# timer register map
Vendor: Texas Instruments
Peripheral module from a debugger description file (folder Keystone2).
Registers are 32-bit, read-write, no defined reset value unless marked. A register's access mark holds for its fields unless they carry their own. Offsets are as the file gives them; lines under a group give offsets from that group; [hi:lo] are bit positions; {n}, {i} and the like mark numbered series; 'fields as' and 'values as' point back to an identical list; <NAME> marks a mode.

## TIMER_19
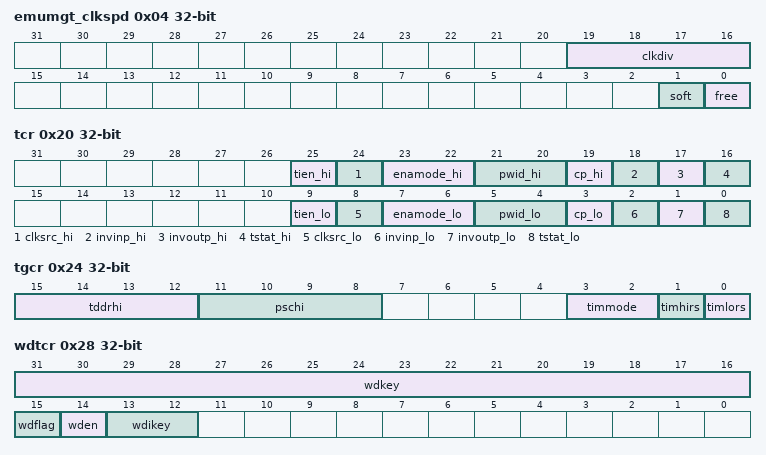
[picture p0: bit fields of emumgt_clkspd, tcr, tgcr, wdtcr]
0x04 emumgt_clkspd
  [19:16] clkdiv, [1] soft, [0] free
0x10 cntlo
  [31:0] cnt
0x14 cnthi
  [31:0] cnt
0x18 prdlo
0x1C prdhi
0x20 tcr
  [25] tien_hi, [24] clksrc_hi, [23:22] enamode_hi, [21:20] pwid_hi, [19] cp_hi, [18] invinp_hi, [17] invoutp_hi, [16] tstat_hi, [9] tien_lo, [8] clksrc_lo, [7:6] enamode_lo, [5:4] pwid_lo, [3] cp_lo, [2] invinp_lo, [1] invoutp_lo, [0] tstat_lo
0x24 tgcr
  [15:12] tddrhi, [11:8] pschi, [3:2] timmode, [1] timhirs, [0] timlors
0x28 wdtcr
  [31:16] wdkey, [15] wdflag, [14] wden, [13:12] wdikey
0x34 rello
0x38 relhi
